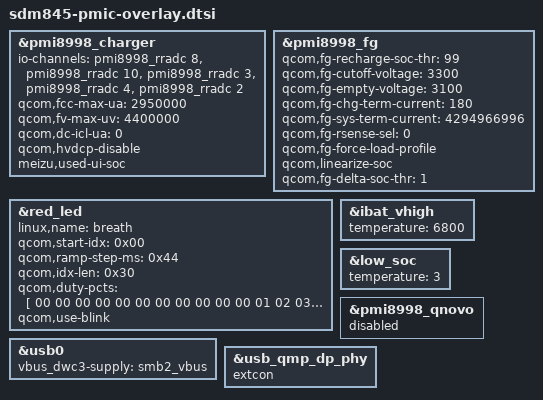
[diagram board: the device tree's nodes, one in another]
/*
 * Copyright (C) 2023 transaero21 <transaero21@elseboot.ru>
 *
 * SPDX-License-Identifier: GPL-2.0
 */

&pmi8998_charger {
	io-channels = <&pmi8998_rradc 8>,
				  <&pmi8998_rradc 10>,
				  <&pmi8998_rradc 3>,
				  <&pmi8998_rradc 4>,
				  <&pmi8998_rradc 2>;
	io-channel-names = "charger_temp",
					   "charger_temp_max",
					   "usbin_i",
					   "usbin_v",
					   "skin_temp";

	qcom,fcc-max-ua = <2950000>;
	qcom,fv-max-uv = <4400000>;
	qcom,dc-icl-ua = <0>;
	qcom,hvdcp-disable;
	meizu,used-ui-soc;
};

&pmi8998_fg {
	qcom,fg-recharge-soc-thr = <99>;
	qcom,fg-cutoff-voltage = <3300>;
	qcom,fg-empty-voltage = <3100>;
	qcom,fg-chg-term-current = <180>;
	qcom,fg-sys-term-current = <4294966996>; /* Meizu =) */
	qcom,fg-rsense-sel = <0>;
	qcom,fg-force-load-profile;
	qcom,linearize-soc;
	qcom,fg-delta-soc-thr = <1>;
};

&red_led {
	linux,name = "breath";
	qcom,start-idx = <0x00>;
	qcom,ramp-step-ms = <0x44>;
	qcom,idx-len = <0x30>;
	qcom,duty-pcts = [
		00 00 00 00 00 00 00 00 00 00 00 01
		02 03 04 05 06 07 08 09 0A 0B 0C 0D
		0C 0B 0A 09 08 07 06 05 04 03 02 01
		00 00 00 00 00 00 00 00 00 00 00 00
	];
	qcom,use-blink;
};

&ibat_vhigh {
	temperature = <6800>;
};

&low_soc {
	temperature = <3>;
};

&pmi8998_qnovo {
	status = "disabled";
};

&usb0 {
	vbus_dwc3-supply = <&smb2_vbus>;
};

/* Erased (deleted) values */
&usb_qmp_dp_phy {
	extcon;
};
